# AT32UC3C1512C device description
Architecture: AVR32_UC3; Family: AVR UC3
Registers are 32-bit, read-write, reset 0x0 unless marked. A register's access mark holds for its fields unless they carry their own. Offsets are from the block's base; [hi:lo] are bit positions; {n}, {i} and the like mark numbered series; 'fields as' and 'values as' point back to an identical list.

## ADCIFA — ADC controller interface with Touch Screen functionality
Instances: ADCIFA 0xfffd2400
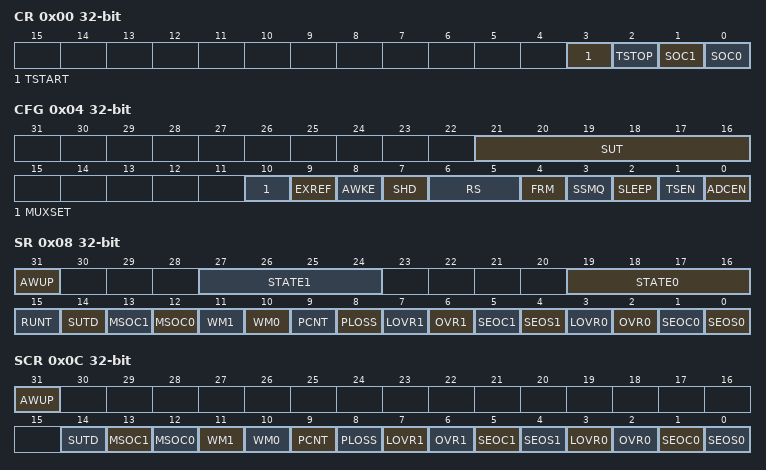
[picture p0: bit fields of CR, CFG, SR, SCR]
0x00 CR wo
  [3] TSTART — Internal timer start bit
  [2] TSTOP — Internal timer stop bit
  [1] SOC1 — Sequencer 1 Start of Conversion
  [0] SOC0 — Sequencer 0 Start Of Conversion
0x04 CFG
  [21:16] SUT — Start-up time
  [10] MUXSET — Multiplexes settle time
  [9] EXREF — External reference
  [8] AWKE — Asynchronous wake-up
  [7] SHD — Sample-and-hold disabled
  [6:5] RS — Reference source
  [4] FRM — Free running mode
  [3] SSMQ — Single sequencer mode
  [2] SLEEP — Sleep mode selection
  [1] TSEN — Touch Screen enable bit
  [0] ADCEN — ADC enable bit
0x08 SR ro
  [31] AWUP — Asynchronous wake-up
  [27:24] STATE1 — Sequencer 1 state register
  [19:16] STATE0 — Sequencer 0 state register
  [15] RUNT — Running timer status
  [14] SUTD — Start-up time done
  [13] MSOC1 — Sequencer 1 missed start-of-conversion
  [12] MSOC0 — Sequencer 0 missed start-of-conversion
  [11] WM1 — Window mode 1
  [10] WM0 — Window mode 0
  [9] PCNT — Pen contact
  [8] PLOSS — No pen contact
  [7] LOVR1 — Sequencer 1 last converted value overrun
  [6] OVR1 — Sequencer 1 overrun error
  [5] SEOC1 — Sequencer 1 end of conversion
  [4] SEOS1 — Sequencer 1 end of sequence
  [3] LOVR0 — Sequencer 0 last converted value overrun
  [2] OVR0 — Sequencer 0 overrun error
  [1] SEOC0 — Sequencer 0 end of conversion
  [0] SEOS0 — Sequencer 0 end of sequence
0x0C SCR wo
  [31] AWUP — Asynchronous wake-up
  [14] SUTD — Start-up done
  [13] MSOC1 — Sequencer 1 Missed SOC
  [12] MSOC0 — Sequencer 0 Missed SOC
  [11] WM1 — Window mode 1
  [10] WM0 — Window mode 0
  [9] PCNT — Pen contact
  [8] PLOSS — No pen contact
  [7] LOVR1 — Sequencer 1 last converted value overrun
  [6] OVR1 — Sequencer 1 overrun error
  [5] SEOC1 — Sequencer 1 end of conversion
  [4] SEOS1 — Sequencer 1 end of sequence
  [3] LOVR0 — Sequencer 0 last converted value overrun
  [2] OVR0 — Sequencer 0 overrun error
  [1] SEOC0 — Sequencer 0 end of conversion
  [0] SEOS0 — Sequencer 0 end of sequence
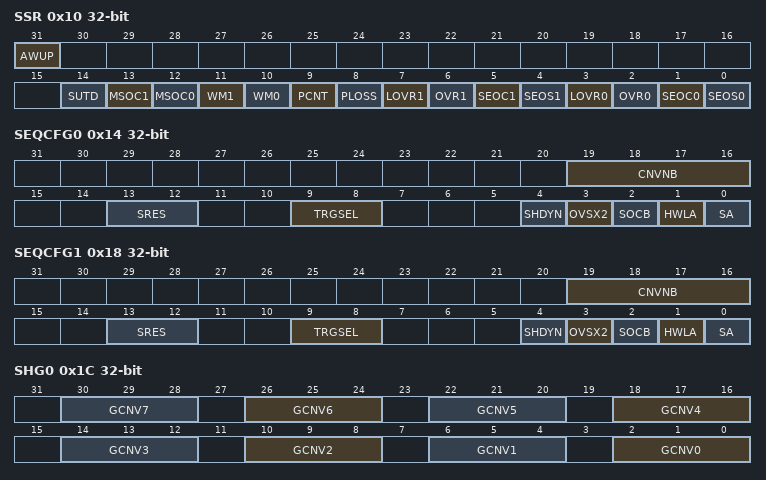
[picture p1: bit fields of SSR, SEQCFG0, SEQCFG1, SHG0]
0x10 SSR wo
  fields as SCR
0x14 SEQCFG0
  [19:16] CNVNB — Number of conversions in a sequence
  [13:12] SRES — Resolution
  [9:8] TRGSEL — Trigger selection
  [4] SHDYN — Sample and hold dynamic mode
  [3] OVSX2 — Oversampling X2
  [2] SOCB — Start of conversion behaviour
  [1] HWLA — Half Word Left Adjust
  [0] SA — Software Acknowledge
0x18 SEQCFG1
  fields as SEQCFG0
0x1C SHG0
  [4n+2:4n] GCNV{n} (n=0..7) — Sequencer 0 conversion {n} sample and hold gain
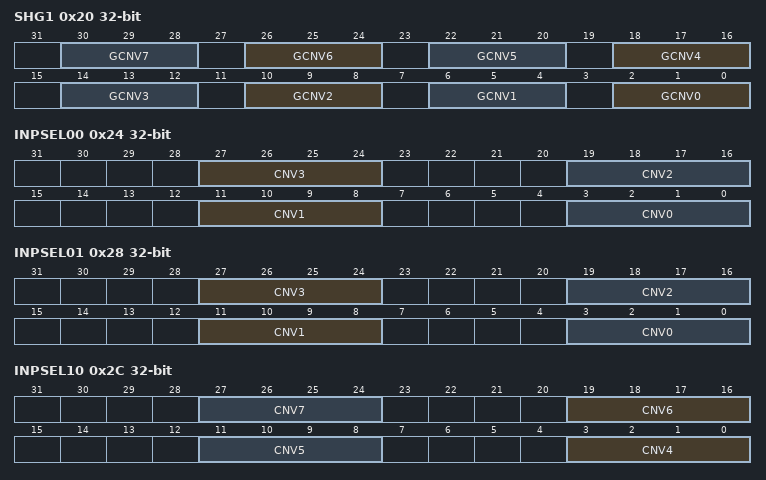
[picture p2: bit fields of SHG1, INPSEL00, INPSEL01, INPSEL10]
0x20 SHG1
  [4n+2:4n] GCNV{n} (n=0..7) — Sequencer 1 conversion {n} sample and hold gain
0x24 INPSEL00
  [27:24] CNV3 — Sequencer 0 INP identifier of the 4th conversion to perform
  [19:16] CNV2 — Sequencer 0 INP identidier of the 3rd conversion to perform
  [11:8] CNV1 — Sequencer 0 INP identifier of the 2nd conversion to perform
  [3:0] CNV0 — Sequencer 0 INP identifier of the 1st conversion to perform
0x28 INPSEL01
  [27:24] CNV3 — Sequencer 1 INP identifier of the 4th conversion to perform
  [19:16] CNV2 — Sequencer 1 INP identidier of the 3rd conversion to perform
  [11:8] CNV1 — Sequencer 1 INP identifier of the 2nd conversion to perform
  [3:0] CNV0 — Sequencer 1 INP identifier of the 1st conversion to perform
0x2C INPSEL10
  [8n-29:8n-32] CNV{n} (n=4..7) — Sequencer 0 INP identifier of the {n+1}th conversion to perform
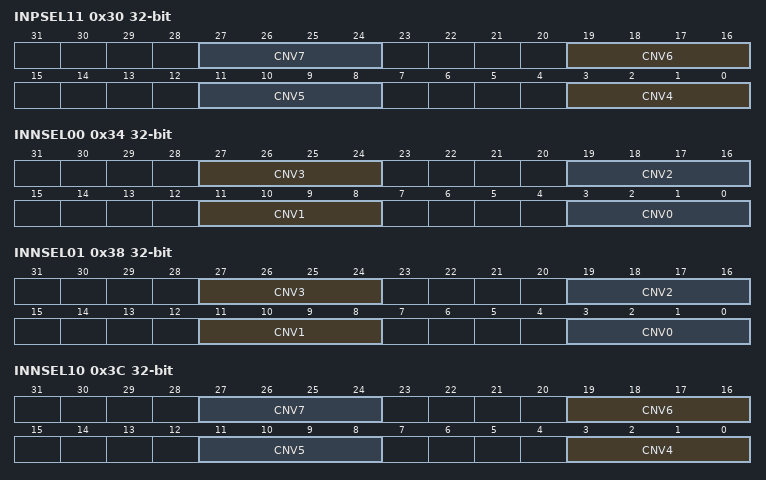
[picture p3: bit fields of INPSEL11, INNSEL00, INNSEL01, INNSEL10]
0x30 INPSEL11
  [8n-29:8n-32] CNV{n} (n=4..7) — Sequencer 1 INP identifier of the {n+1}th conversion to perform
0x34 INNSEL00
  [27:24] CNV3 — Sequencer 0 INN identifier of the 4th conversion to perform
  [19:16] CNV2 — Sequencer 0 INN identidier of the 3rd conversion to perform
  [11:8] CNV1 — Sequencer 0 INN identifier of the 2nd conversion to perform
  [3:0] CNV0 — Sequencer 0 INN identifier of the 1st conversion to perform
0x38 INNSEL01
  [27:24] CNV3 — Sequencer 1 INN identifier of the 4th conversion to perform
  [19:16] CNV2 — Sequencer 1 INN identifier of the 3rd conversion to perform
  [11:8] CNV1 — Sequencer 1 INN identifier of the 2nd conversion to perform
  [3:0] CNV0 — Sequencer 1 INN identifier of the 1st conversion to perform
0x3C INNSEL10
  [8n-29:8n-32] CNV{n} (n=4..7) — Sequencer 0 INN identifier of the {n+1}th conversion to perform
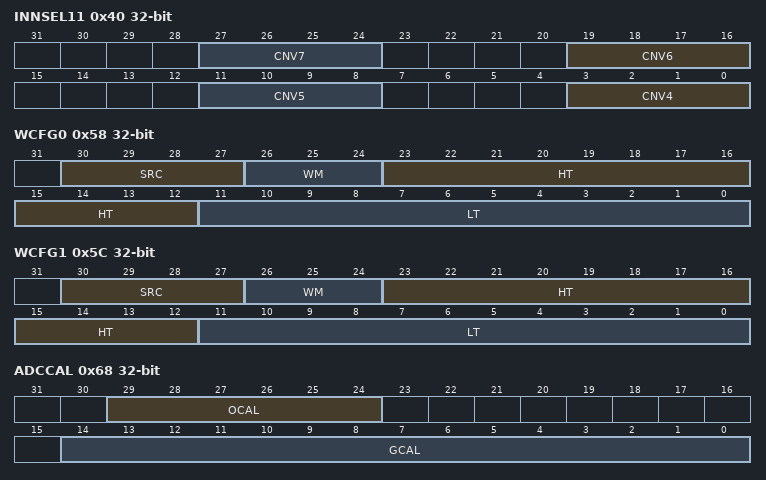
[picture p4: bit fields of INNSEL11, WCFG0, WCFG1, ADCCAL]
0x40 INNSEL11
  [8n-29:8n-32] CNV{n} (n=4..7) — Sequencer 1 INN identifier of the {n+1}th conversion to perform
0x44 CKDIV
  [8:0] CNT — Max counter value
0x48 ITIMER
  [16:0] ITMC — Internal Timer Max Counter
0x58 WCFG0
  [30:27] SRC — Source selection
  [26:24] WM — Window mode
  [23:12] HT — High Threshold
  [11:0] LT — Low Threshold
0x5C WCFG1
  fields as WCFG0
0x60 LCV0 ro
  [31:0] LCV — Last converted value
0x64 LCV1 ro
  [31:0] LCV — Last converted value
0x68 ADCCAL
  [29:24] OCAL — Offset calibration
  [14:0] GCAL — Gain calibration
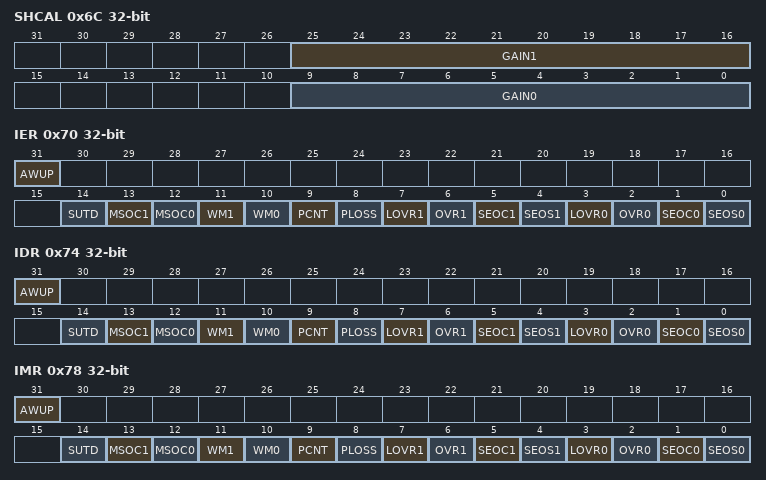
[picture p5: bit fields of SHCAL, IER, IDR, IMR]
0x6C SHCAL
  [25:16] GAIN1 — SH1 gain calibration
  [9:0] GAIN0 — SH0 gain calibration
0x70 IER
  [31] AWUP — Asynchronous wake-up occured
  [14] SUTD — Start-up time done at least once sincle last clear
  [13] MSOC1 — Sequencer 1 missed start-of-conversion
  [12] MSOC0 — Sequencer 0 missed start-of-conversion
  [11] WM1 — Window mode 1
  [10] WM0 — Window mode 0
  [9] PCNT — Pen contact
  [8] PLOSS — Pen loss
  [7] LOVR1 — Sequencer 1 last resad value overrun
  [6] OVR1 — Sequencer 1 overrun
  [5] SEOC1 — Sequencer 1 end of conversion
  [4] SEOS1 — Sequencer 1 end of sequence
  [3] LOVR0 — Sequencer 0 last resad value overrun
  [2] OVR0 — Sequencer 0 overrun
  [1] SEOC0 — Sequencer 0 end of conversion
  [0] SEOS0 — Sequencer 0 end of sequence
0x74 IDR
  fields as IER
0x78 IMR
  fields as IER
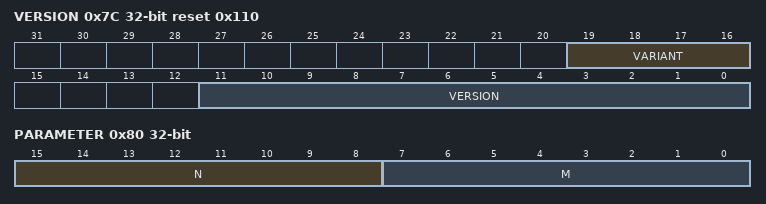
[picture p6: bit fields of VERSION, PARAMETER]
0x7C VERSION ro reset 0x110
  [19:16] VARIANT — Bug fixes, minor variants
  [11:0] VERSION — Module Version
0x80 PARAMETER ro reset not defined
  [15:8] N — Number of channels
  [7:0] M — Number of states per sequencer
{0x84+4i} RESx[{i}] (i=0..15) access not given reset not defined
  [31:0] RES — Result register
